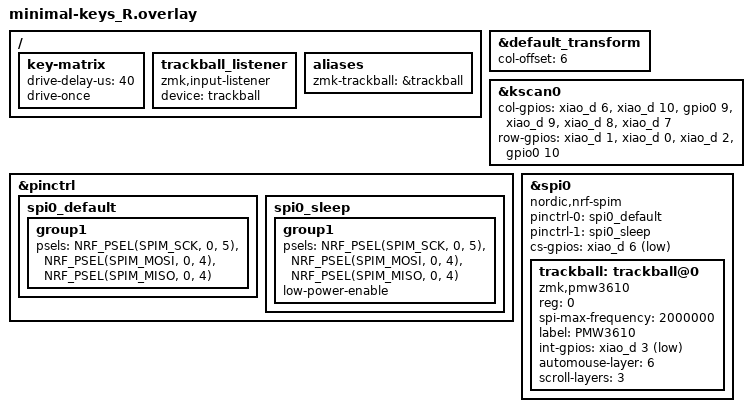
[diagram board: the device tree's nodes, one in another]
#include "minimal-keys.dtsi"

&default_transform {
    col-offset = <6>;
};

&kscan0 {
        col-gpios
            = <&xiao_d 6 GPIO_ACTIVE_HIGH>
            , <&xiao_d 10 GPIO_ACTIVE_HIGH> 
            , <&gpio0  9 GPIO_ACTIVE_HIGH>
            , <&xiao_d 9 GPIO_ACTIVE_HIGH> 
            , <&xiao_d 8 GPIO_ACTIVE_HIGH> 
            , <&xiao_d 7 GPIO_ACTIVE_HIGH> 
            ;
    row-gpios 
        =<&xiao_d 1 (GPIO_ACTIVE_HIGH | GPIO_PULL_DOWN)>,  /* 行ピンはプルダウンで安定化 */
                <&xiao_d 0 (GPIO_ACTIVE_HIGH | GPIO_PULL_DOWN)>,
                <&xiao_d 2 (GPIO_ACTIVE_HIGH | GPIO_PULL_DOWN)>,
                <&gpio0 10 (GPIO_ACTIVE_HIGH | GPIO_PULL_DOWN)>;
};

/ {
    key-matrix {
        drive-delay-us = <40>;   /* Drive each column for 40 µs */
        drive-once;              /* Return columns to Hi-Z between scans */
    };


    trackball_listener {
        compatible = "zmk,input-listener";
        device = <&trackball>;

    };
};

&pinctrl {
    spi0_default: spi0_default {
        group1 {
            psels = <NRF_PSEL(SPIM_SCK, 0, 5)>,
                <NRF_PSEL(SPIM_MOSI, 0, 4)>,
                <NRF_PSEL(SPIM_MISO, 0, 4)>;
        };
    };

    spi0_sleep: spi0_sleep {
        group1 {
            psels = <NRF_PSEL(SPIM_SCK, 0, 5)>,
                <NRF_PSEL(SPIM_MOSI, 0, 4)>,
                <NRF_PSEL(SPIM_MISO, 0, 4)>;
            low-power-enable;
        };
    };
};

&spi0 {
    status = "okay";
    compatible = "nordic,nrf-spim";
    pinctrl-0 = <&spi0_default>;
    pinctrl-1 = <&spi0_sleep>;
    pinctrl-names = "default", "sleep";
    cs-gpios = <&xiao_d 6 GPIO_ACTIVE_LOW>;

    trackball: trackball@0 {
        status = "okay";
        compatible = "zmk,pmw3610";
        reg = <0>;
        spi-max-frequency = <2000000>;
        label = "PMW3610";
        /*irq-gpios =  <&xiao_d 3 (GPIO_ACTIVE_LOW | GPIO_PULL_UP)>;*/
         /* Motion interrupt (MOTION pin) on D3, active low */
        int-gpios = <&xiao_d 3 (GPIO_ACTIVE_LOW | GPIO_PULL_UP)>;
        automouse-layer = <6>;
        scroll-layers = <3>;

    };
};


/ {
    aliases {
        zmk-trackball = &trackball;
    };
};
